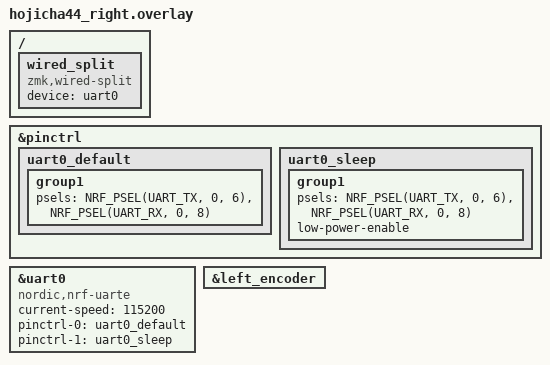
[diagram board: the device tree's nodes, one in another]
/*
 * Hojicha44 RIGHT half overlay — DRAFT (see hojicha44.dtsi header).
 *
 * Deliberately IDENTICAL UART map to the left (TX=P0.06=D1, RX=P0.08=D0):
 * the right half already crosses TX/RX in copper (D1->RING1, D0->TIP), so
 * the straight cable delivers left-TX into right-RX and right-TX into
 * left-RX with no firmware swap. If the cable is ever redefined, this is
 * the one place that changes.
 */
#include "hojicha44.dtsi"

&pinctrl {
    uart0_default: uart0_default {
        group1 {
            psels = <NRF_PSEL(UART_TX, 0, 6)>, <NRF_PSEL(UART_RX, 0, 8)>;
        };
    };
    uart0_sleep: uart0_sleep {
        group1 {
            psels = <NRF_PSEL(UART_TX, 0, 6)>, <NRF_PSEL(UART_RX, 0, 8)>;
            low-power-enable;
        };
    };
};

&uart0 {
    compatible = "nordic,nrf-uarte";
    status = "okay";
    current-speed = <115200>;
    pinctrl-0 = <&uart0_default>;
    pinctrl-1 = <&uart0_sleep>;
    pinctrl-names = "default", "sleep";
};

/ {
    wired_split {
        compatible = "zmk,wired-split";
        device = <&uart0>;
    };
};

&left_encoder {
    status = "okay";
};
